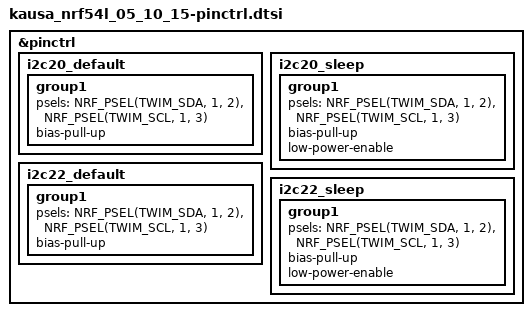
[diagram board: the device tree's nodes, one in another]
/*
 * Copyright (c) 2024 Nordic Semiconductor
 * SPDX-License-Identifier: Apache-2.0
 */

&pinctrl {
	/omit-if-no-ref/ i2c20_default: i2c20_default {
		group1 {
			psels = <NRF_PSEL(TWIM_SDA, 1, 2)>,
				<NRF_PSEL(TWIM_SCL, 1, 3)>;
			bias-pull-up;
		};
	};

	/omit-if-no-ref/ i2c20_sleep: i2c20_sleep {
		group1 {
			psels = <NRF_PSEL(TWIM_SDA, 1, 2)>,
				<NRF_PSEL(TWIM_SCL, 1, 3)>;
			bias-pull-up;
			low-power-enable;
		};
	};

	/omit-if-no-ref/ i2c22_default: i2c22_default {
		group1 {
			psels = <NRF_PSEL(TWIM_SDA, 1, 2)>,
				<NRF_PSEL(TWIM_SCL, 1, 3)>;
			bias-pull-up;
		};
	};

	/omit-if-no-ref/ i2c22_sleep: i2c22_sleep {
		group1 {
			psels = <NRF_PSEL(TWIM_SDA, 1, 2)>,
				<NRF_PSEL(TWIM_SCL, 1, 3)>;
			bias-pull-up;
			low-power-enable;
		};
	};
};
